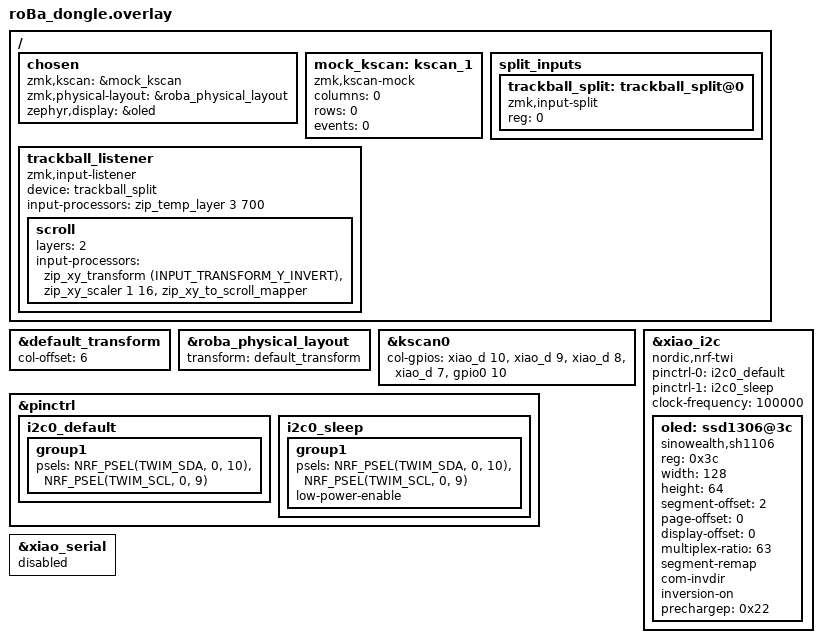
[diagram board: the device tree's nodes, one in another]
#include "roBa.dtsi"
#include <dt-bindings/zmk/bt.h>
#include <input/processors.dtsi>
#include <zephyr/dt-bindings/input/input-event-codes.h>
#include <dt-bindings/zmk/input_transform.h>



&default_transform {
    col-offset = <6>;
};

&roba_physical_layout {
    transform = <&default_transform>;
};

&kscan0 {
        col-gpios
            = <&xiao_d 10 GPIO_ACTIVE_HIGH>
            , <&xiao_d 9 GPIO_ACTIVE_HIGH> 
            , <&xiao_d 8 GPIO_ACTIVE_HIGH> 
            , <&xiao_d 7 GPIO_ACTIVE_HIGH> 
            , <&gpio0 10 GPIO_ACTIVE_HIGH>
            ;
};

/ {
    chosen {
        zmk,kscan = &mock_kscan;
        zmk,physical-layout = &roba_physical_layout;
        zephyr,display = &oled;
    };

    mock_kscan: kscan_1 {
        compatible = "zmk,kscan-mock";
        columns = <0>;
        rows = <0>;
        events = <0>;
    };
};

/ {
    split_inputs {
        #address-cells = <1>;
        #size-cells = <0>;

        trackball_split: trackball_split@0 {
            compatible = "zmk,input-split";
            reg = <0>;
        };
    };

    trackball_listener: trackball_listener {
        compatible = "zmk,input-listener";
        status = "disabled";
        device = <&trackball_split>;
    };
};

&trackball_listener {
    status = "okay";
    input-processors = <&zip_temp_layer 3 700>;

    scroll {
        layers = <2>;
        input-processors = <&zip_xy_transform (INPUT_TRANSFORM_Y_INVERT)>, <&zip_xy_scaler 1 16>, <&zip_xy_to_scroll_mapper>;
    };
};



&pinctrl {
    i2c0_default: i2c0_default {
        group1 {
            psels = <NRF_PSEL(TWIM_SDA, 0, 10)>,
                    <NRF_PSEL(TWIM_SCL, 0, 9)>;
        };
    };
      
    i2c0_sleep: i2c0_sleep {
        group1 {
            psels = <NRF_PSEL(TWIM_SDA, 0, 10)>,
                    <NRF_PSEL(TWIM_SCL, 0, 9)>;
            low-power-enable;
        };
    };
};


&xiao_i2c {
    status = "okay";
    compatible = "nordic,nrf-twi";
    pinctrl-0 = <&i2c0_default>;
    pinctrl-1 = <&i2c0_sleep>;
    pinctrl-names = "default", "sleep";
    
    clock-frequency = <100000>;

    oled: ssd1306@3c {
        compatible = "sinowealth,sh1106";
        reg = <0x3c>;
        width = <128>;
        height = <64>;
        segment-offset = <2>;
        page-offset = <0>;
        display-offset = <0>;
        multiplex-ratio = <63>;
        segment-remap;
        com-invdir;
        inversion-on;
        prechargep = <0x22>;
    };
};

&xiao_serial { status = "disabled"; };

